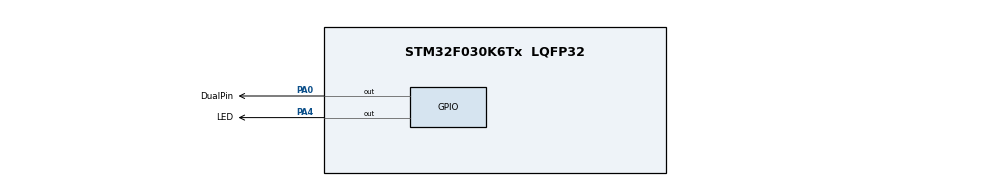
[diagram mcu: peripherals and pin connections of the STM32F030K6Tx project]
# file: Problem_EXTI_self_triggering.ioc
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Mcu.Family=STM32F0
Mcu.Name=STM32F030K6Tx
Mcu.Package=LQFP32
NVIC.TIM17_IRQn=true\:0\:0\:false\:false\:true\:true\:true\:true
PA0.GPIO_Label=DualPin
PA0.GPIO_ModeDefaultOutputPP=GPIO_MODE_OUTPUT_OD
PA0.GPIO_PuPd=GPIO_PULLUP
PA0.PinState=GPIO_PIN_SET
PA0.Signal=GPIO_Output
PA13.Mode=Serial_Wire
PA13.Signal=SYS_SWDIO
PA14.Mode=Serial_Wire
PA14.Signal=SYS_SWCLK
PA4.GPIO_Label=LED
PA4.Signal=GPIO_Output
ProjectManager.HeapSize=0x200
ProjectManager.StackSize=0x400
ProjectManager.TargetToolchain=STM32CubeIDE
TIM17.Period=500-1
TIM17.Prescaler=8000-1
VP_TIM17_VS_ClockSourceINT.Mode=Enable_Timer
board=custom

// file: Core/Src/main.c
/* USER CODE BEGIN Header */
/**
 *
 * WORKING VERY WELL. MAGIC WORTH KEEPING.
 *
 * PA0 is configured as a common-drain but with EXTI - not a combo available from CubeMX.
 *     magic sauce is added to MX_GPIO_Init() to turn just common-drain into EXTI as well.
 *
 * PA0 has an external switch to GND, simulating another common drain device connected.
 * This is fine. but this code also asserts PA0 low, and we don't want that creating an
 * EXTI interrupt - we only want interrupts on the same line from outside.
 *
 * So:
 * 1. EXTI ISR will react to external interrupt and start htim17 which begins looking at PA0
 *    to transfer data between devices.
 * 2. We don't want this subsequent activity causing interrupts: beyond the start bit,
 *    we use a time-loop to read the port.
 *
 * 3. Therefore, we turn off the EXTI IRQs when the start bit is detected, and
 *    turn them back on again at the end of the data packet.
 *
 * 4. But the turn-on causes a fresh EXTI IRQ, even though there's not -ve edge
 *     on PA0!
 *
 * 5. Look at HAL_TIM_PeriodElapsedCallBack() for the solution - the while loop just
 *    before NVIC_EnableIRQ()
 *
 * 6. SOlution found here: https://community.st.com/s/question/0D50X00009XkgqeSAB/clear-pending-interrupts
 *
  ******************************************************************************
  * @file           : main.c
  * @brief          : Main program body
  ******************************************************************************
  * @attention
  *
  * Copyright (c) 2023 STMicroelectronics.
  * All rights reserved.
  *
  * This software is licensed under terms that can be found in the LICENSE file
  * in the root directory of this software component.
  * If no LICENSE file comes with this software, it is provided AS-IS.
  *
  ******************************************************************************
  */
/* USER CODE END Header */
#include "main.h"

TIM_HandleTypeDef htim17;

/* USER CODE BEGIN PV */
uint8_t htim17_tick = 0;
uint8_t halfBitCounter = 0;

/* USER CODE END PV */

void SystemClock_Config(void);
static void MX_GPIO_Init(void);
static void MX_TIM17_Init(void);

int main(void)
{

  /* MCU Configuration--------------------------------------------------------*/

  /* Reset of all peripherals, Initializes the Flash interface and the Systick. */
  HAL_Init();

  /* Configure the system clock */
  SystemClock_Config();

  /* Initialize all configured peripherals */
  MX_GPIO_Init();
  MX_TIM17_Init();

  /* Infinite loop */
  while (1)
  {

  }
}

void SystemClock_Config(void)
{
  LL_FLASH_SetLatency(LL_FLASH_LATENCY_0);
  while(LL_FLASH_GetLatency() != LL_FLASH_LATENCY_0)
  {
  }
  LL_RCC_HSI_Enable();

   /* Wait till HSI is ready */
  while(LL_RCC_HSI_IsReady() != 1)
  {

  }
  LL_RCC_HSI_SetCalibTrimming(16);
  LL_RCC_SetAHBPrescaler(LL_RCC_SYSCLK_DIV_1);
  LL_RCC_SetAPB1Prescaler(LL_RCC_APB1_DIV_1);
  LL_RCC_SetSysClkSource(LL_RCC_SYS_CLKSOURCE_HSI);

   /* Wait till System clock is ready */
  while(LL_RCC_GetSysClkSource() != LL_RCC_SYS_CLKSOURCE_STATUS_HSI)
  {

  }
  LL_SetSystemCoreClock(8000000);

   /* Update the time base */
  if (HAL_InitTick (TICK_INT_PRIORITY) != HAL_OK)
  {
    Error_Handler();
  }
}

static void MX_TIM17_Init(void)
{

  htim17.Instance = TIM17;
  htim17.Init.Prescaler = 8000-1;
  htim17.Init.CounterMode = TIM_COUNTERMODE_UP;
  htim17.Init.Period = 500-1;
  htim17.Init.ClockDivision = TIM_CLOCKDIVISION_DIV1;
  htim17.Init.RepetitionCounter = 0;
  htim17.Init.AutoReloadPreload = TIM_AUTORELOAD_PRELOAD_DISABLE;
  if (HAL_TIM_Base_Init(&htim17) != HAL_OK)
  {
    Error_Handler();
  }

}

static void MX_GPIO_Init(void)
{
  LL_GPIO_InitTypeDef GPIO_InitStruct = {0};
/* USER CODE BEGIN MX_GPIO_Init_1 */
  LL_EXTI_InitTypeDef EXTI_InitStruct = {0};

   LL_SYSCFG_SetEXTISource(LL_SYSCFG_EXTI_PORTA, LL_SYSCFG_EXTI_LINE0);

   EXTI_InitStruct.Line_0_31 = LL_EXTI_LINE_0;
   EXTI_InitStruct.LineCommand = ENABLE;
   EXTI_InitStruct.Mode = LL_EXTI_MODE_IT;
   EXTI_InitStruct.Trigger = LL_EXTI_TRIGGER_FALLING;
   LL_EXTI_Init(&EXTI_InitStruct);

/* USER CODE END MX_GPIO_Init_1 */

  /* GPIO Ports Clock Enable */
  LL_AHB1_GRP1_EnableClock(LL_AHB1_GRP1_PERIPH_GPIOA);

  /**/
  LL_GPIO_SetOutputPin(DualPin_GPIO_Port, DualPin_Pin);

  /**/
  LL_GPIO_ResetOutputPin(LED_GPIO_Port, LED_Pin);

  /**/
  GPIO_InitStruct.Pin = DualPin_Pin;
  GPIO_InitStruct.Mode = LL_GPIO_MODE_OUTPUT;
  GPIO_InitStruct.Speed = LL_GPIO_SPEED_FREQ_LOW;
  GPIO_InitStruct.OutputType = LL_GPIO_OUTPUT_OPENDRAIN;
  GPIO_InitStruct.Pull = LL_GPIO_PULL_UP;
  LL_GPIO_Init(DualPin_GPIO_Port, &GPIO_InitStruct);

  /**/
  GPIO_InitStruct.Pin = LED_Pin;
  GPIO_InitStruct.Mode = LL_GPIO_MODE_OUTPUT;
  GPIO_InitStruct.Speed = LL_GPIO_SPEED_FREQ_LOW;
  GPIO_InitStruct.OutputType = LL_GPIO_OUTPUT_PUSHPULL;
  GPIO_InitStruct.Pull = LL_GPIO_PULL_NO;
  LL_GPIO_Init(LED_GPIO_Port, &GPIO_InitStruct);

/* USER CODE BEGIN MX_GPIO_Init_2 */

  /* EXTI interrupt init*/
   NVIC_SetPriority(EXTI0_1_IRQn, 0);
   NVIC_EnableIRQ(EXTI0_1_IRQn);

/* USER CODE END MX_GPIO_Init_2 */
}

/* USER CODE BEGIN 4 */

void HAL_TIM_PeriodElapsedCallback(TIM_HandleTypeDef *htim)
{
	switch (halfBitCounter)
	{
	case 2:
	case 4:
		LL_GPIO_TogglePin(DualPin_GPIO_Port, DualPin_Pin);
		LL_GPIO_TogglePin(LED_GPIO_Port, LED_Pin);
		break;

	case 8:
		HAL_TIM_Base_Stop_IT(&htim17);

		while (HAL_NVIC_GetPendingIRQ(EXTI0_1_IRQn))	// or	NVIC_GetPendingIRQ(EXTI0_1_IRQn)
		{
			__HAL_GPIO_EXTI_CLEAR_IT(LL_EXTI_LINE_0); 	// or	LL_EXTI_ClearFlag_0_31(LL_EXTI_LINE_0);
			HAL_NVIC_ClearPendingIRQ(EXTI0_1_IRQn);		// or	NVIC_ClearPendingIRQ (EXTI0_1_IRQn);
		}

		NVIC_EnableIRQ(EXTI0_1_IRQn);
		break;
	default:
		break;
	}

	halfBitCounter++;
}

void EXTI0_1_IRQHandler(void)
{
  /* USER CODE BEGIN EXTI0_1_IRQn 0 */

  /* USER CODE END EXTI0_1_IRQn 0 */
  if (LL_EXTI_IsActiveFlag_0_31(LL_EXTI_LINE_0) != RESET)
  {
    LL_EXTI_ClearFlag_0_31(LL_EXTI_LINE_0);
    /* USER CODE BEGIN LL_EXTI_LINE_0 */

    NVIC_DisableIRQ(EXTI0_1_IRQn);

    halfBitCounter = 0;

    if (htim17.State == HAL_TIM_STATE_READY)
    {
    	HAL_TIM_Base_Start_IT(&htim17);
    }

    /* USER CODE END LL_EXTI_LINE_0 */
  }
  /* USER CODE BEGIN EXTI0_1_IRQn 1 */

  /* USER CODE END EXTI0_1_IRQn 1 */
}

/* USER CODE END 4 */

void Error_Handler(void)
{
  __disable_irq();
  while (1)
  {
  }
}
